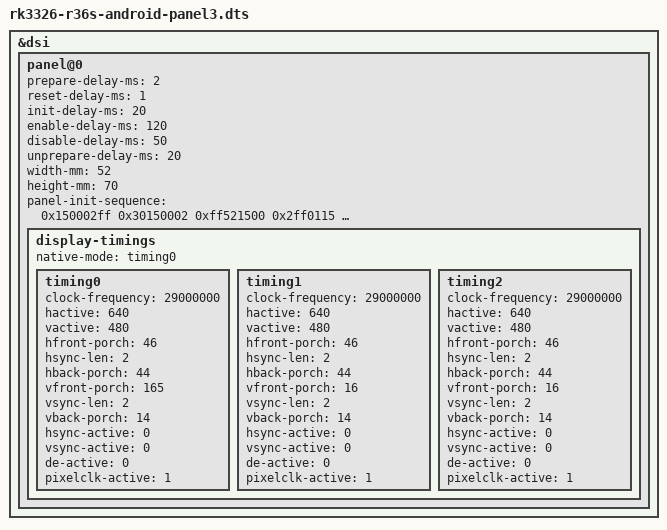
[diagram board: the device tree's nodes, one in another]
// SPDX-License-Identifier: (GPL-2.0+ OR MIT)
/*
 * Copyright (c) 2020 Hardkernel Co., Ltd
 */

/dts-v1/;
#include "rk3326-r36s-android.dtsi"


&dsi {
	panel@0 {
			prepare-delay-ms = <2>;
			reset-delay-ms = <1>;
			init-delay-ms = <20>;
			enable-delay-ms = <120>;
			disable-delay-ms = <50>;
			unprepare-delay-ms = <20>;
			width-mm = <52>;
			height-mm = <70>;
			panel-init-sequence = <0x150002ff 0x30150002 0xff521500 0x2ff0115 0x2e300 0x15000203 0x40150002 0x4001500 0x2050315 0x22412 0x15000225 0x1e150002 0x266f1500 0x2275215 0x22867 0x15000229 0x1150002 0x2adf1500 0x2379c15 0x238a7 0x15000239 0x53150002 0x44001500 0x2493c15 0x259fe 0x15000280 0x20150002 0x91771500 0x2927715 0x2a055 0x150002a1 0x50150002 0xa49c1500 0x2a70215 0x2a801 0x150002a9 0x21150002 0xaafc1500 0x2ab2815 0x2ac06 0x150002ad 0x6150002 0xae061500 0x2af0315 0x2b008 0x150002b1 0x26150002 0xb2281500 0x2b32815 0x2b433 0x150002b5 0x8150002 0xb6261500 0x2b70815 0x2b826 0x1500022c 0x22150002 0x5c401500 0x2c00015 0x2c100 0x150002c2 0x150002 0xff301500 0x2ff5215 0x2ff02 0x150002b0 0xb150002 0xb1161500 0x2b21715 0x2b32c 0x150002b4 0x32150002 0xb53b1500 0x2b62915 0x2b740 0x150002b8 0xd150002 0xb9051500 0x2ba1215 0x2bb10 0x150002bc 0x12150002 0xbd151500 0x2be1915 0x2bf0e 0x150002c0 0x16150002 0xc10a1500 0x2d00c15 0x2d117 0x150002d2 0x14150002 0xd32e1500 0x2d43215 0x2d53c 0x150002d6 0x22150002 0xd73d1500 0x2d80d15 0x2d907 0x150002da 0x13150002 0xdb131500 0x2dc1115 0x2dd15 0x150002de 0x19150002 0xdf101500 0x2e01715 0x2e10a 0x150002ff 0x30150002 0xff521500 0x2ff0315 0x2002a 0x15000201 0x2a150002 0x22a1500 0x2032a15 0x20461 0x15000205 0x80150002 0x6c71500 0x2070115 0x20882 0x15000209 0x83150002 0x302a1500 0x2312a15 0x2322a 0x15000233 0x2a150002 0x34a11500 0x235c515 0x23680 0x15000237 0x23150002 0x40821500 0x2418315 0x24280 0x15000243 0x81150002 0x44551500 0x245e615 0x246e5 0x15000247 0x55150002 0x48e81500 0x249e715 0x25002 0x15000251 0x1150002 0x52041500 0x2530315 0x25455 0x15000255 0xea150002 0x56e91500 0x2575515 0x258ec 0x15000259 0xeb150002 0x7e021500 0x27f8015 0x2e05a 0x150002b1 0x150002 0xb40e1500 0x2b50f15 0x2b604 0x150002b7 0x7150002 0xb8061500 0x2b90515 0x2ba0f 0x150002c7 0x150002 0xca0e1500 0x2cb0f15 0x2cc04 0x150002cd 0x7150002 0xce061500 0x2cf0515 0x2d00f 0x15000281 0xf150002 0x840e1500 0x2850f15 0x28607 0x15000287 0x4150002 0x88051500 0x2890615 0x28a00 0x15000297 0xf150002 0x9a0e1500 0x29b0f15 0x29c07 0x1500029d 0x4150002 0x9e051500 0x29f0615 0x2a000 0x150002ff 0x30150002 0xff521500 0x2ff0215 0x20101 0x15000202 0xda150002 0x3ba1500 0x204a815 0x2059a 0x15000206 0x70150002 0x7ff1500 0x2089115 0x20990 0x1500020a 0xff150002 0xb8f1500 0x20c6015 0x20d58 0x1500020e 0x48150002 0xf381500 0x2102b15 0x2ff30 0x150002ff 0x52150002 0xff001500 0x2360215 0x23a70 0x5c80111 0x5140129>;

			display-timings {
				native-mode = <&timing0>;

				timing0 {
					clock-frequency = <29000000>;
					hactive = <640>;
					vactive = <480>;
					hfront-porch = <46>;
					hsync-len = <2>;
					hback-porch = <44>;
					vfront-porch = <165>;	/* was 16: 77.4 Hz; 59.94 Hz like Panel 4, same pixel clock */
					vsync-len = <2>;
					vback-porch = <14>;
					hsync-active = <0>;
					vsync-active = <0>;
					de-active = <0>;
					pixelclk-active = <1>;
				};

				timing1 {
					clock-frequency = <29000000>;
					hactive = <640>;
					vactive = <480>;
					hfront-porch = <46>;
					hsync-len = <2>;
					hback-porch = <44>;
					vfront-porch = <16>;
					vsync-len = <2>;
					vback-porch = <14>;
					hsync-active = <0>;
					vsync-active = <0>;
					de-active = <0>;
					pixelclk-active = <1>;
				};

				timing2 {
					clock-frequency = <29000000>;
					hactive = <640>;
					vactive = <480>;
					hfront-porch = <46>;
					hsync-len = <2>;
					hback-porch = <44>;
					vfront-porch = <16>;
					vsync-len = <2>;
					vback-porch = <14>;
					hsync-active = <0>;
					vsync-active = <0>;
					de-active = <0>;
					pixelclk-active = <1>;
				};
			};
	};
};
